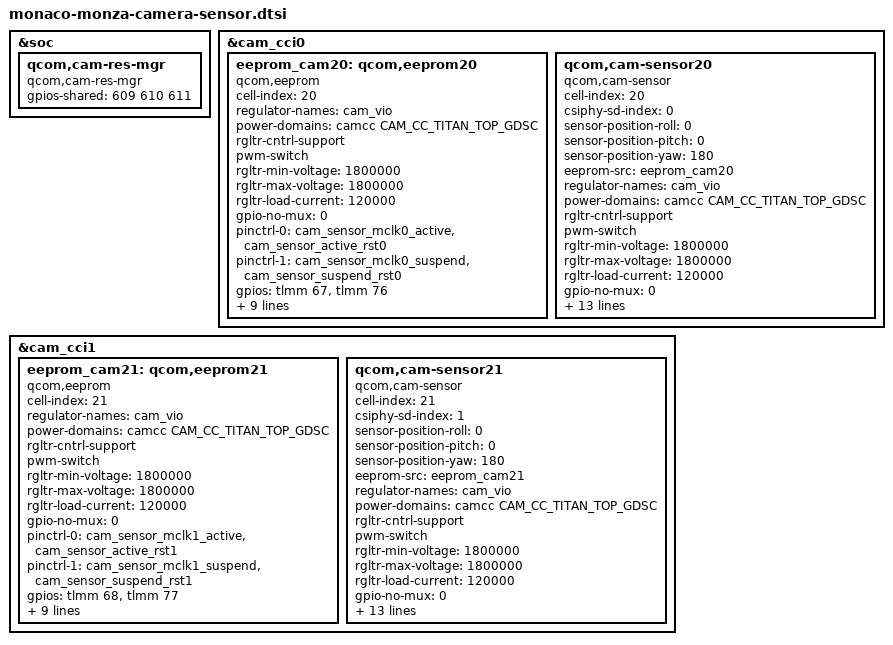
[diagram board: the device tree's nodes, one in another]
// SPDX-License-Identifier: BSD-3-Clause
/*
 * Copyright (c) Qualcomm Technologies, Inc. and/or its subsidiaries.
 */
#include <dt-bindings/msm-camera.h>

&soc {
	qcom,cam-res-mgr {
		compatible = "qcom,cam-res-mgr";
		status = "ok";
		gpios-shared = <609 610 611>;
	};
};

&cam_cci0 {

	/*cam0-imx577-eeprom*/
	eeprom_cam20: qcom,eeprom20 {
		cell-index = <20>;
		compatible = "qcom,eeprom";
		regulator-names = "cam_vio";
		power-domains = <&camcc CAM_CC_TITAN_TOP_GDSC>;
		rgltr-cntrl-support;
		pwm-switch;
		rgltr-min-voltage = <1800000>;
		rgltr-max-voltage = <1800000>;
		rgltr-load-current = <120000>;
		gpio-no-mux = <0>;
		pinctrl-names = "cam_default", "cam_suspend";
		pinctrl-0 = <&cam_sensor_mclk0_active
				 &cam_sensor_active_rst0>;
		pinctrl-1 = <&cam_sensor_mclk0_suspend
				 &cam_sensor_suspend_rst0>;
		gpios = <&tlmm 67 0>,
			<&tlmm 76 0>;
		gpio-reset = <1>;
		gpio-req-tbl-num = <0 1>;
		gpio-req-tbl-flags = <1 0>;
		gpio-req-tbl-label = "CAM_MCLK0",
		                       "CAMIF_RESET0";
		sensor-mode = <0>;
		cci-master = <0>;
		status = "ok";
		clocks = <&camcc CAM_CC_MCLK0_CLK>;
		clock-names = "cam_clk";
		clock-cntl-level = "nominal";
		clock-rates = <24000000>;
	};

	/*cam0-imx577*/
	qcom,cam-sensor20 {
		cell-index = <20>;
		compatible = "qcom,cam-sensor";
		csiphy-sd-index = <0>;
		sensor-position-roll = <0>;
		sensor-position-pitch = <0>;
		sensor-position-yaw = <180>;
		eeprom-src = <&eeprom_cam20>;
		regulator-names = "cam_vio";
		power-domains = <&camcc CAM_CC_TITAN_TOP_GDSC>;
		rgltr-cntrl-support;
		pwm-switch;
		rgltr-min-voltage = <1800000>;
		rgltr-max-voltage = <1800000>;
		rgltr-load-current = <120000>;
		gpio-no-mux = <0>;
		pinctrl-names = "cam_default", "cam_suspend";
		pinctrl-0 = <&cam_sensor_mclk0_active
		                &cam_sensor_active_rst0>;
		pinctrl-1 = <&cam_sensor_mclk0_suspend
		                &cam_sensor_suspend_rst0>;
		gpios = <&tlmm 67 0>,
			<&tlmm 76 0>;
		gpio-reset = <1>;
		gpio-req-tbl-num = <0 1>;
		gpio-req-tbl-flags   	 = <1 0>;
		gpio-req-tbl-label = "CAM_MCLK0",
		                       "CAMIF_RESET0";
		cci-master = <0>;
		clocks = <&camcc CAM_CC_MCLK0_CLK>;
		clock-names = "cam_clk";
		clock-cntl-level = "nominal";
		clock-rates = <24000000>;
		status = "ok";
	};
};


&cam_cci1 {

	/*cam1-imx577-eeprom*/
	eeprom_cam21: qcom,eeprom21 {
		cell-index = <21>;
		compatible = "qcom,eeprom";
		regulator-names = "cam_vio";
		power-domains = <&camcc CAM_CC_TITAN_TOP_GDSC>;
		rgltr-cntrl-support;
		pwm-switch;
		rgltr-min-voltage = <1800000>;
		rgltr-max-voltage = <1800000>;
		rgltr-load-current = <120000>;
		gpio-no-mux = <0>;
		pinctrl-names = "cam_default", "cam_suspend";
		pinctrl-0 = <&cam_sensor_mclk1_active
				 &cam_sensor_active_rst1>;
		pinctrl-1 = <&cam_sensor_mclk1_suspend
				 &cam_sensor_suspend_rst1>;
		gpios = <&tlmm 68 0>,
			<&tlmm 77 0>;
		gpio-reset = <1>;
		gpio-req-tbl-num = <0 1>;
		gpio-req-tbl-flags = <1 0>;
		gpio-req-tbl-label = "CAM_MCLK1",
					"CAMIF_RESET1";
		sensor-mode = <0>;
		cci-master = <0>;
		status = "ok";
		clocks = <&camcc CAM_CC_MCLK1_CLK>;
		clock-names = "cam_clk";
		clock-cntl-level = "nominal";
		clock-rates = <24000000>;
	};

	/*cam1-imx577*/
	qcom,cam-sensor21 {
		cell-index = <21>;
		compatible = "qcom,cam-sensor";
		csiphy-sd-index = <1>;
		sensor-position-roll = <0>;
		sensor-position-pitch = <0>;
		sensor-position-yaw = <180>;
		eeprom-src = <&eeprom_cam21>;
		regulator-names = "cam_vio";
		power-domains = <&camcc CAM_CC_TITAN_TOP_GDSC>;
		rgltr-cntrl-support;
		pwm-switch;
		rgltr-min-voltage = <1800000>;
		rgltr-max-voltage = <1800000>;
		rgltr-load-current = <120000>;
		gpio-no-mux = <0>;
		pinctrl-names = "cam_default", "cam_suspend";
		pinctrl-0 = <&cam_sensor_mclk1_active
		                &cam_sensor_active_rst1>;
		pinctrl-1 = <&cam_sensor_mclk1_suspend
		                &cam_sensor_suspend_rst1>;
		gpios = <&tlmm 68 0>,
			<&tlmm 77 0>;
		gpio-reset = <1>;
		gpio-req-tbl-num = <0 1>;
		gpio-req-tbl-flags   	 = <1 0>;
		gpio-req-tbl-label = "CAM_MCLK1",
		                       "CAMIF_RESET1";
		cci-master = <0>;
		clocks = <&camcc CAM_CC_MCLK1_CLK>;
		clock-names = "cam_clk";
		clock-cntl-level = "nominal";
		clock-rates = <24000000>;
		status = "ok";
	};
};
